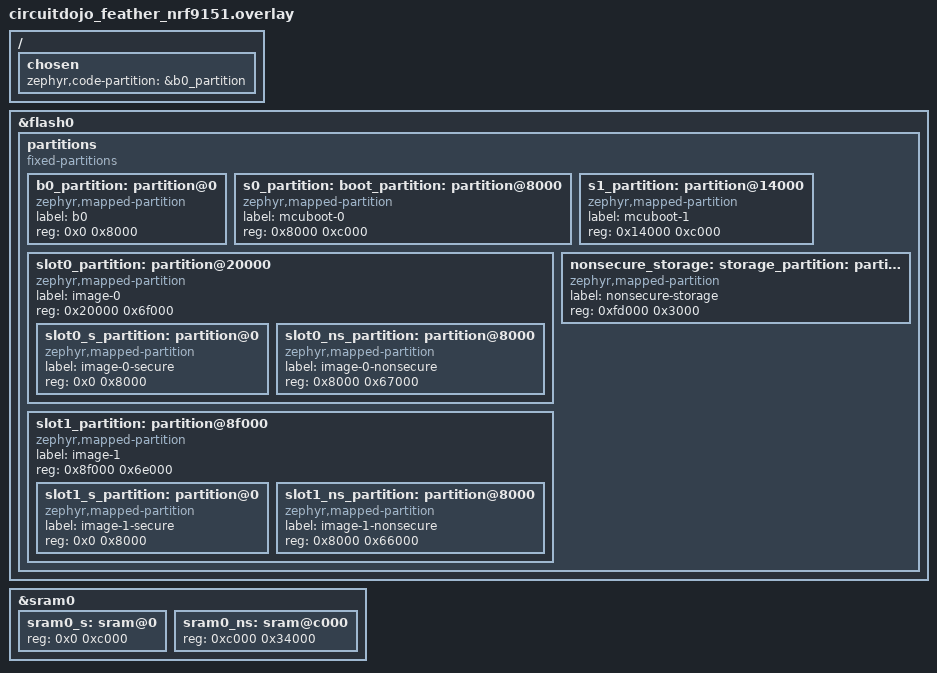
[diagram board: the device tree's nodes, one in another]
/*
 * Copyright (c) 2026 Circuit Dojo LLC
 *
 * SPDX-License-Identifier: LicenseRef-Nordic-5-Clause
 */

/ {
	chosen {
		zephyr,code-partition = &b0_partition;
	};
};

/*
 * Flash partition layout for the nRF9151 Feather with B0 and updatable MCUboot.
 * Keep this in sync with boards/circuitdojo_feather_nrf9151_ns.overlay and the
 * MCUboot overlay.
 */

/delete-node/ &boot_partition;
/delete-node/ &slot0_partition;
/delete-node/ &slot1_partition;
/delete-node/ &tfm_ps_partition;
/delete-node/ &tfm_its_partition;
/delete-node/ &tfm_otp_partition;
/delete-node/ &storage_partition;

&flash0 {
	partitions {
		compatible = "fixed-partitions";
		#address-cells = <1>;
		#size-cells = <1>;

		b0_partition: partition@0 {
			compatible = "zephyr,mapped-partition";
			label = "b0";
			reg = <0x0 0x8000>;
		};

		s0_partition: boot_partition: partition@8000 {
			compatible = "zephyr,mapped-partition";
			label = "mcuboot-0";
			reg = <0x8000 0xc000>;
		};

		s1_partition: partition@14000 {
			compatible = "zephyr,mapped-partition";
			label = "mcuboot-1";
			reg = <0x14000 0xc000>;
		};

		slot0_partition: partition@20000 {
			compatible = "zephyr,mapped-partition";
			label = "image-0";
			reg = <0x20000 0x6f000>;
			ranges = <0x0 0x20000 0x6f000>;
			#address-cells = <1>;
			#size-cells = <1>;

			slot0_s_partition: partition@0 {
				compatible = "zephyr,mapped-partition";
				label = "image-0-secure";
				reg = <0x0 0x8000>;
			};

			slot0_ns_partition: partition@8000 {
				compatible = "zephyr,mapped-partition";
				label = "image-0-nonsecure";
				reg = <0x8000 0x67000>;
			};
		};

		slot1_partition: partition@8f000 {
			compatible = "zephyr,mapped-partition";
			label = "image-1";
			reg = <0x8f000 0x6e000>;
			ranges = <0x0 0x8f000 0x6e000>;
			#address-cells = <1>;
			#size-cells = <1>;

			slot1_s_partition: partition@0 {
				compatible = "zephyr,mapped-partition";
				label = "image-1-secure";
				reg = <0x0 0x8000>;
			};

			slot1_ns_partition: partition@8000 {
				compatible = "zephyr,mapped-partition";
				label = "image-1-nonsecure";
				reg = <0x8000 0x66000>;
			};
		};

		nonsecure_storage: storage_partition: partition@fd000 {
			compatible = "zephyr,mapped-partition";
			label = "nonsecure-storage";
			reg = <0xfd000 0x3000>;
		};
	};
};

/* B0 and MCUboot must use matching SRAM layouts. */

/delete-node/ &sram0_s;
/delete-node/ &sram0_ns;

&sram0 {
	sram0_s: sram@0 {
		reg = <0x0 0xc000>;
	};

	sram0_ns: sram@c000 {
		reg = <0xc000 0x34000>;
	};
};
